# Template register map
Vendor: VendorName Co.Ltd; Series: SeriesName; File version: 1.2
CPU: CM7 r0p1, little endian, MPU, FPU, 4 interrupt priority bits
Registers are 32-bit, read-write, no defined reset value unless marked. A register's access mark holds for its fields unless they carry their own. Offsets are from the block's base; [hi:lo] are bit positions; lines under a group give offsets from that group; {n}, {i} and the like mark numbered series.

## EMATH — EMATH register list
Base 0x400B6000
0x00 OUTBASE — EMATH the base address of output area register
  [31:0] OUTBASE — EMATH OUTBASE[31:0] bit: base address register for the output region
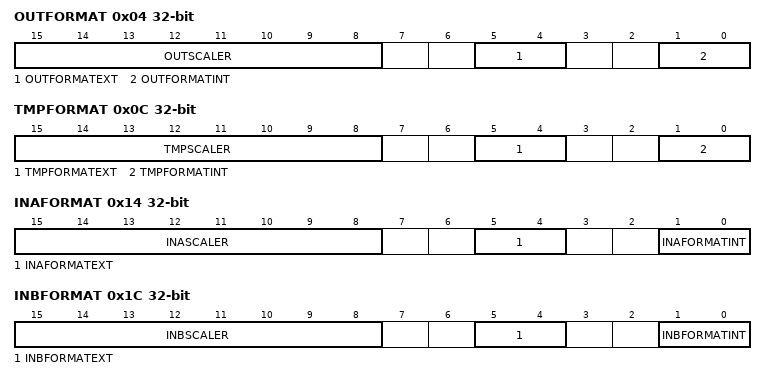
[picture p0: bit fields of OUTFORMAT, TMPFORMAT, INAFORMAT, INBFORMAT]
0x04 OUTFORMAT — EMATH output format register
  [15:8] OUTSCALER — EMATH OUTSCALER[7:0] bit: output scaler value
  [5:4] OUTFORMATEXT — EMATH OUTFORMATEXT[1:0] bit: output external format
  [1:0] OUTFORMATINT — EMATH OUTFORMATINT[1:0] bit: output internal format
0x08 TMPBASE — EMATH the base address of temporary area register
  [31:0] TMPBASE — EMATH TMPBASE[31:0] bit: base address register for the temporary region
0x0C TMPFORMAT — EMATH temporary format register
  [15:8] TMPSCALER — EMATH TMPSCALER[7:0] bit: temporary scaler value
  [5:4] TMPFORMATEXT — EMATH TMPFORMATEXT[1:0] bit: temporary external format
  [1:0] TMPFORMATINT — EMATH TMPFORMATINT[1:0] bit: temporary internal format
0x10 INABASE — EMATH the base address of input A area register
  [31:0] INABASE — EMATH INABASE[31:0] bit: base address register for the input A region
0x14 INAFORMAT — EMATH input A format register
  [15:8] INASCALER — EMATH INASCALER[7:0] bit: input A scale value
  [5:4] INAFORMATEXT — EMATH INAFORMATEXT[1:0] bit: input A external format
  [1:0] INAFORMATINT — EMATH INAFORMATINT[1:0] bit: input A internal format
0x18 INBBASE — EMATH the base address of input B area register
  [31:0] INBBASE — EMATH INBBASE[31:0] bit: base address register for the input B region
0x1C INBFORMAT — EMATH input B format register
  [15:8] INBSCALER — EMATH INBSCALER[7:0] bit: input B scaler value
  [5:4] INBFORMATEXT — EMATH INBFORMATEXT[1:0] bit: input B external format
  [1:0] INBFORMATINT — EMATH INBFORMATINT[1:0] bit: input B internal format
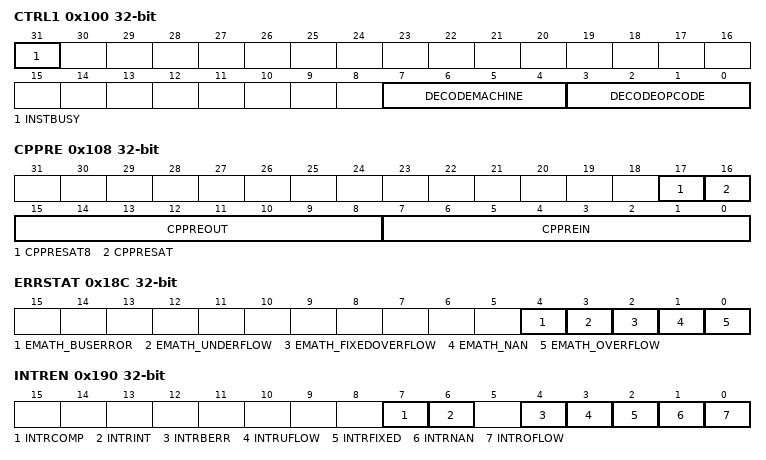
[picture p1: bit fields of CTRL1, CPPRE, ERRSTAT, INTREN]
0x100 CTRL1 — EMATH control register
  [31] INSTBUSY ro — EMATH INSTBUSY bit: instruction busy signal when high indicates processing is on
  [7:4] DECODEMACHINE — EMATH DECODEMACHINE[3:0] bit: calculation decode machine
  [3:0] DECODEOPCODE — EMATH DECODEOPCODE[3:0] bit: opcode specific to decode_machine
0x104 LENGTH — EMATH length register
  [31:0] INSTLENGTH — EMATH INSTLENGTH[31:0] bit: instruction of length register
0x108 CPPRE — EMATH predefined allocation register
  [17] CPPRESAT8 — EMATH CPPRESAT8 bit: saturation with 8
  [16] CPPRESAT — EMATH CPPRESAT bit: saturation
  [15:8] CPPREOUT — EMATH CPPREOUT[7:0] bit: fixed point output
  [7:0] CPPREIN — EMATH CPPREIN[7:0] bit: scaling of input
0x10C MISC — EMATH scaling factor in matrix operations register
  [31:0] INSTMISC — EMATH INSTMISC[31:0] bit: used for scale factor
0x110 CURSORY — EMATH approximate mode register
  [0] CURSORY — EMATH CURSORY bit: cursory mode enable selection
0x180 CORDICX — EMATH cordic X register
  [31:0] CORDICX — EMATH CORDICX[31:0] bit: CORDIC input x
0x184 CORDICY — EMATH cordic Y register
  [31:0] CORDICY — EMATH CORDICY[31:0] bit: CORDIC input y
0x188 CORDICZ — EMATH cordic Z register
  [31:0] CORDICZ — EMATH CORDICZ[31:0] bit: CORDIC input z
0x18C ERRSTAT — EMATH error state register
  [4] EMATH_BUSERROR — EMATH EMATH_BUSERROR bit: bus error flag
  [3] EMATH_UNDERFLOW — EMATH EMATH_UNDERFLOW bit: underflow flag
  [2] EMATH_FIXEDOVERFLOW — EMATH EMATH_FIXEDOVERFLOW bit: fixed-point number overflow flag
  [1] EMATH_NAN — EMATH EMATH_NAN bit: NAN flag
  [0] EMATH_OVERFLOW — EMATH EMATH_OVERFLOW bit: overflow flag
0x190 INTREN — EMATH interrupt enable register
  [7] INTRCOMP — EMATH INTRCOMP bit: enable interruption request on instruction completion
  [6] INTRINT — EMATH INTRINT bit: global interruption flag enable
  [4] INTRBERR — EMATH INTRBERR bit: enable interruption request on AHBM bus error generation
  [3] INTRUFLOW — EMATH INTRUFLOW bit: enable interruption request on underflow generation
  [2] INTRFIXED — EMATH INTRFIXED bit: enable interruption request on fixed-pointer number overflow generation
  [1] INTRNAN — EMATH INTRNAN bit: enable interruption request on NAN error generation
  [0] INTROFLOW — EMATH INTROFLOW bit: enable interruption request on overflow generation
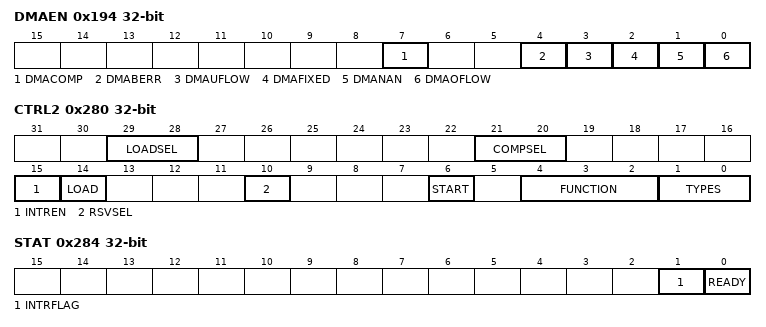
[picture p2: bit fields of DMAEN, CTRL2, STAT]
0x194 DMAEN — EMATH DMA enable register
  [7] DMACOMP — EMATH DMACOMP bit: enable DMA request on instruction completion
  [4] DMABERR — EMATH DMABERR bit: enable DMA request on AHBM bus error generation
  [3] DMAUFLOW — EMATH DMAUFLOW bit: enable DMA request on underflow generation
  [2] DMAFIXED — EMATH DMAFIXED bit: enable DMA request on fixed-pointer number overflow generation
  [1] DMANAN — EMATH DMANAN bit: enable DMA request on NAN error generation
  [0] DMAOFLOW — EMATH DMAOFLOW bit: enable DMA request on overflow generation
0x198 INTRSTAT — EMATH interrupt state register
  [0] INTRSTAT — EMATH INTRSTAT bit: interrupt status register
{0x200+4i} GPREGSX[{i}] (i=0..15) — EMATH general register group 0~15
  [31:0] GPREGS — EMATH GPREGS[31:0] bit: general purpose register bank x
{0x240+4i} COMPREGSX[{i}] (i=0..7) — EMATH calculation register group 0~7
  [31:0] COMPREGS — EMATH COMPREGS[31:0] bit: compute register bank x
0x280 CTRL2 — EMATH cp interface control register
  [29:28] LOADSEL — EMATH LOADSEL[1:0] bit: output type and calc unit select
  [21:20] COMPSEL — EMATH COMPSEL[1:0] bit: input type and clac unit select
  [15] INTREN — EMATH INTREN bit: calc finish interrupt enable
  [14] LOAD — EMATH LOAD bit: write 1 load result to read register
  [10] RSVSEL — EMATH RSVSEL bit: result select
  [6] START — EMATH START bit: start calc
  [4:2] FUNCTION — EMATH FUNCTION[2:0] bit: function select from calc types
  [1:0] TYPES — EMATH TYPES[1:0] bit: calc types
0x284 STAT — EMATH cp interface state register
  [1] INTRFLAG — EMATH INTRFLAG bit: completed interrupt flag
  [0] READY ro — EMATH READY bit: READY signal
0x290 WDATA0 — EMATH cp interface write data register 0
  [31:0] WDATA — EMATH WDATA[31:0] bit: write data register 0
0x294 WDATA1 — EMATH cp interface write data register 1
  [31:0] WDATA — EMATH WDATA[31:0] bit: write data register 1
0x298 RDATA0 ro — EMATH cp interface read data register 0
  [31:0] RDATA — EMATH RDATA[31:0] bit: read data register 0
0x29C RDATA1 ro — EMATH cp interface read data register 1
  [31:0] RDATA — EMATH RDATA[31:0] bit: read data register 1
